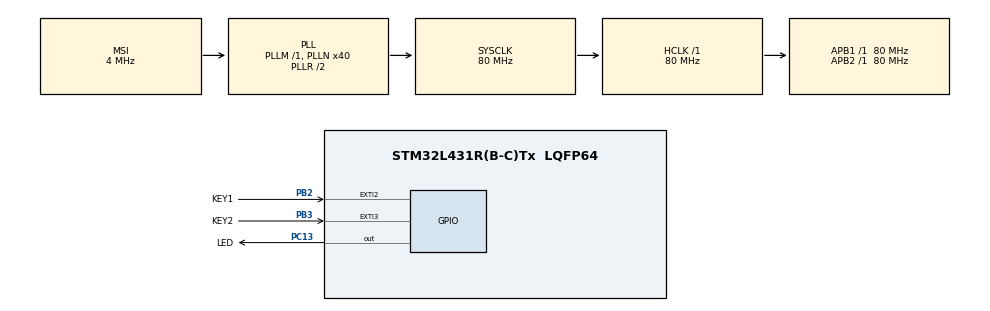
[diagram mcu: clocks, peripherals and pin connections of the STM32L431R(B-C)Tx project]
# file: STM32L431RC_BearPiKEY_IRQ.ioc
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Mcu.Family=STM32L4
Mcu.Name=STM32L431R(B-C)Tx
Mcu.Package=LQFP64
NVIC.EXTI2_IRQn=true\:0\:0\:false\:false\:true\:true
NVIC.EXTI3_IRQn=true\:0\:0\:false\:false\:true\:true
NVIC.PriorityGroup=NVIC_PRIORITYGROUP_4
PB2.GPIO_Label=KEY1
PB2.GPIO_ModeDefaultEXTI=GPIO_MODE_IT_FALLING
PB2.GPIO_PuPd=GPIO_PULLUP
PB2.Signal=GPXTI2
PB3\ (JTDO-TRACESWO).GPIO_Label=KEY2
PB3\ (JTDO-TRACESWO).GPIO_ModeDefaultEXTI=GPIO_MODE_IT_FALLING
PB3\ (JTDO-TRACESWO).GPIO_PuPd=GPIO_PULLUP
PB3\ (JTDO-TRACESWO).Signal=GPXTI3
PC13.GPIO_Label=LED
PC13.Signal=GPIO_Output
ProjectManager.HeapSize=0x200
ProjectManager.StackSize=0x400
ProjectManager.TargetToolchain=MDK-ARM V5
RCC.AHBFreq_Value=80000000
RCC.APB1Freq_Value=80000000
RCC.APB1TimFreq_Value=80000000
RCC.APB2Freq_Value=80000000
RCC.APB2TimFreq_Value=80000000
RCC.CortexFreq_Value=80000000
RCC.HCLKFreq_Value=80000000
RCC.HSE_VALUE=8000000
RCC.HSI48_VALUE=48000000
RCC.HSI_VALUE=16000000
RCC.LSE_VALUE=32768
RCC.MSI_VALUE=4000000
RCC.PLLN=40
RCC.SYSCLKFreq_VALUE=80000000
RCC.SYSCLKSource=RCC_SYSCLKSOURCE_PLLCLK
RCC.VCOOutputFreq_Value=160000000
board=custom

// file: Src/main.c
/**
  ******************************************************************************
  * @file           : main.c
  * @brief          : Main program body
  ******************************************************************************
  ** This notice applies to any and all portions of this file
  * that are not between comment pairs USER CODE BEGIN and
  * USER CODE END. Other portions of this file, whether
  * inserted by the user or by software development tools
  * are owned by their respective copyright owners.
  *
  * COPYRIGHT(c) 2019 STMicroelectronics
  *
  * Redistribution and use in source and binary forms, with or without modification,
  * are permitted provided that the following conditions are met:
  *   1. Redistributions of source code must retain the above copyright notice,
  *      this list of conditions and the following disclaimer.
  *   2. Redistributions in binary form must reproduce the above copyright notice,
  *      this list of conditions and the following disclaimer in the documentation
  *      and/or other materials provided with the distribution.
  *   3. Neither the name of STMicroelectronics nor the names of its contributors
  *      may be used to endorse or promote products derived from this software
  *      without specific prior written permission.
  *
  * THIS SOFTWARE IS PROVIDED BY THE COPYRIGHT HOLDERS AND CONTRIBUTORS "AS IS"
  * AND ANY EXPRESS OR IMPLIED WARRANTIES, INCLUDING, BUT NOT LIMITED TO, THE
  * IMPLIED WARRANTIES OF MERCHANTABILITY AND FITNESS FOR A PARTICULAR PURPOSE ARE
  * DISCLAIMED. IN NO EVENT SHALL THE COPYRIGHT HOLDER OR CONTRIBUTORS BE LIABLE
  * FOR ANY DIRECT, INDIRECT, INCIDENTAL, SPECIAL, EXEMPLARY, OR CONSEQUENTIAL
  * DAMAGES (INCLUDING, BUT NOT LIMITED TO, PROCUREMENT OF SUBSTITUTE GOODS OR
  * SERVICES; LOSS OF USE, DATA, OR PROFITS; OR BUSINESS INTERRUPTION) HOWEVER
  * CAUSED AND ON ANY THEORY OF LIABILITY, WHETHER IN CONTRACT, STRICT LIABILITY,
  * OR TORT (INCLUDING NEGLIGENCE OR OTHERWISE) ARISING IN ANY WAY OUT OF THE USE
  * OF THIS SOFTWARE, EVEN IF ADVISED OF THE POSSIBILITY OF SUCH DAMAGE.
  *
  ******************************************************************************
  */
#include "main.h"
#include "stm32l4xx_hal.h"
#include "gpio.h"

/* USER CODE BEGIN PV */
/* Private variables ---------------------------------------------------------*/

/* USER CODE END PV */

void SystemClock_Config(void);

/* USER CODE BEGIN PFP */
/* Private function prototypes -----------------------------------------------*/

/* USER CODE END PFP */

int main(void)
{

  /* MCU Configuration----------------------------------------------------------*/

  /* Reset of all peripherals, Initializes the Flash interface and the Systick. */
  HAL_Init();

  /* Configure the system clock */
  SystemClock_Config();

  /* Initialize all configured peripherals */
  MX_GPIO_Init();

  /* Infinite loop */
  while (1)
  {

  /* USER CODE BEGIN 3 */
  HAL_Delay(5000);//用于检测延时是否影响中断检测
  }
  /* USER CODE END 3 */

}

void SystemClock_Config(void)
{

  RCC_OscInitTypeDef RCC_OscInitStruct;
  RCC_ClkInitTypeDef RCC_ClkInitStruct;

    /**Initializes the CPU, AHB and APB busses clocks
    */
  RCC_OscInitStruct.OscillatorType = RCC_OSCILLATORTYPE_MSI;
  RCC_OscInitStruct.MSIState = RCC_MSI_ON;
  RCC_OscInitStruct.MSICalibrationValue = 0;
  RCC_OscInitStruct.MSIClockRange = RCC_MSIRANGE_6;
  RCC_OscInitStruct.PLL.PLLState = RCC_PLL_ON;
  RCC_OscInitStruct.PLL.PLLSource = RCC_PLLSOURCE_MSI;
  RCC_OscInitStruct.PLL.PLLM = 1;
  RCC_OscInitStruct.PLL.PLLN = 40;
  RCC_OscInitStruct.PLL.PLLP = RCC_PLLP_DIV7;
  RCC_OscInitStruct.PLL.PLLQ = RCC_PLLQ_DIV2;
  RCC_OscInitStruct.PLL.PLLR = RCC_PLLR_DIV2;
  if (HAL_RCC_OscConfig(&RCC_OscInitStruct) != HAL_OK)
  {
    _Error_Handler(__FILE__, __LINE__);
  }

    /**Initializes the CPU, AHB and APB busses clocks
    */
  RCC_ClkInitStruct.ClockType = RCC_CLOCKTYPE_HCLK|RCC_CLOCKTYPE_SYSCLK
                              |RCC_CLOCKTYPE_PCLK1|RCC_CLOCKTYPE_PCLK2;
  RCC_ClkInitStruct.SYSCLKSource = RCC_SYSCLKSOURCE_PLLCLK;
  RCC_ClkInitStruct.AHBCLKDivider = RCC_SYSCLK_DIV1;
  RCC_ClkInitStruct.APB1CLKDivider = RCC_HCLK_DIV1;
  RCC_ClkInitStruct.APB2CLKDivider = RCC_HCLK_DIV1;

  if (HAL_RCC_ClockConfig(&RCC_ClkInitStruct, FLASH_LATENCY_4) != HAL_OK)
  {
    _Error_Handler(__FILE__, __LINE__);
  }

    /**Configure the main internal regulator output voltage
    */
  if (HAL_PWREx_ControlVoltageScaling(PWR_REGULATOR_VOLTAGE_SCALE1) != HAL_OK)
  {
    _Error_Handler(__FILE__, __LINE__);
  }

    /**Configure the Systick interrupt time
    */
  HAL_SYSTICK_Config(HAL_RCC_GetHCLKFreq()/1000);

    /**Configure the Systick
    */
  HAL_SYSTICK_CLKSourceConfig(SYSTICK_CLKSOURCE_HCLK);

  /* SysTick_IRQn interrupt configuration */
  HAL_NVIC_SetPriority(SysTick_IRQn, 0, 0);
}

/* USER CODE BEGIN 4 */
void HAL_GPIO_EXTI_Callback(uint16_t GPIO_Pin)//外部中断回调函数
 {
  if(GPIO_Pin==KEY1_Pin)//检测是否为外部中断2
	{
	   HAL_GPIO_TogglePin(LED_GPIO_Port,LED_Pin);
	}
	if(GPIO_Pin==KEY2_Pin)//检测是否为外部中断3
	{
	   HAL_GPIO_TogglePin(LED_GPIO_Port,LED_Pin);
	}
 }

/* USER CODE END 4 */

void _Error_Handler(char *file, int line)
{
  while(1)
  {
  }
}

/************************ (C) COPYRIGHT STMicroelectronics *****END OF FILE****/
